AUTOSAR XML (schema 4-3-0)
package /ComponentTypes
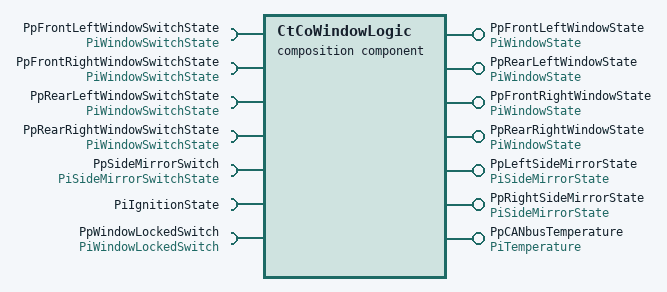
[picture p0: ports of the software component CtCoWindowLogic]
  composition sw component type CtCoWindowLogic
    5 x require port:
      PpFrontLeftWindowSwitchState: nonqueued-receiver-com-spec{data-element=DeWindowSwitchState, init-value=0}, required-interface=PiWindowSwitchState
      PpFrontRightWindowSwitchState: nonqueued-receiver-com-spec{data-element=DeWindowSwitchState, init-value=0}, required-interface=PiWindowSwitchState
      PpRearLeftWindowSwitchState: nonqueued-receiver-com-spec{data-element=DeWindowSwitchState, init-value=0}, required-interface=PiWindowSwitchState
      PpRearRightWindowSwitchState: nonqueued-receiver-com-spec{data-element=DeWindowSwitchState, init-value=0}, required-interface=PiWindowSwitchState
      PpSideMirrorSwitch: nonqueued-receiver-com-spec{data-element=DeSideMirrorSelectionState, filter=data-filter-type=ALWAYS, init-value=0}, required-interface=PiSideMirrorSwitchState
    6 x provide port:
      PpFrontLeftWindowState: nonqueued-sender-com-spec=DeWindowState, provided-interface=PiWindowState
      PpRearLeftWindowState: nonqueued-sender-com-spec=DeWindowState, provided-interface=PiWindowState
      PpFrontRightWindowState: nonqueued-sender-com-spec=DeWindowState, provided-interface=PiWindowState
      PpRearRightWindowState: nonqueued-sender-com-spec=DeWindowState, provided-interface=PiWindowState
      PpLeftSideMirrorState: provided-interface=PiSideMirrorState
      PpRightSideMirrorState: provided-interface=PiSideMirrorState
    require port PiIgnitionState: nonqueued-receiver-com-spec{data-element=DeIgnitionState, init-value=0}, required-interface=PiIgnitionState
    require port PpWindowLockedSwitch: nonqueued-receiver-com-spec{data-element=DeWindowLock, init-value=0}, required-interface=PiWindowLockedSwitch  # This Port will accept incoming boolean value from the connected actuator. If the value returns yes(trigger) the runnable will run.
    provide port PpCANbusTemperature: nonqueued-sender-com-spec=DeTemp, provided-interface=PiTemperature
    5 x component:
      CpAtWindowSwitchDecoder: type=CtAtWindowSwitchDecoder
      CtAtSideMirrorDecoder: type=CtAtSideMirrorDecoder
      CtAtWindowOpener: type=CtAtWindowOpener
      CtSaJoypadY: type=CtSaJoypadY
      CtSaJoypadX: type=CtSaJoypadX
    delegate CpAtWindowSwitchDecoder.PpFrontLeftWindowSwitchState <-> outer port PpFrontLeftWindowSwitchState
    delegate CpAtWindowSwitchDecoder.PpFrontRightWindowSwitchState <-> outer port PpFrontRightWindowSwitchState
    delegate CpAtWindowSwitchDecoder.PpRearLeftWindowSwitchState <-> outer port PpRearLeftWindowSwitchState
    delegate CpAtWindowSwitchDecoder.PpRearRightWindowSwitchState <-> outer port PpRearRightWindowSwitchState
    connect CpAtWindowSwitchDecoder.PpFrontLeftWindowState -> CtAtWindowOpener.PpInFrontLeftWindowState
    connect CpAtWindowSwitchDecoder.PpFrontRightWindowState -> CtAtWindowOpener.PpInFrontRightWindowState
    connect CpAtWindowSwitchDecoder.PpRearLeftWindowState -> CtAtWindowOpener.PpInRearLeftWindowState
    connect CpAtWindowSwitchDecoder.PpRearRightWindowState -> CtAtWindowOpener.PpInRearRightWindowState
    delegate CtAtSideMirrorDecoder.PpSideMirrorSwitchState <-> outer port PpSideMirrorSwitch
    delegate CtAtWindowOpener.PpOutLeftSideMirrorState <-> outer port PpLeftSideMirrorState
    delegate CtAtWindowOpener.PpOutRightSideMirrorState <-> outer port PpRightSideMirrorState
    delegate CtAtWindowOpener.PpOutFrontLeftWindowState <-> outer port PpFrontLeftWindowState
    delegate CtAtWindowOpener.PpOutFrontRightWindowState <-> outer port PpFrontRightWindowState
    delegate CtAtWindowOpener.PpOutRearLeftWindowState <-> outer port PpRearLeftWindowState
    delegate CtAtWindowOpener.PpOutRearRightWindowState <-> outer port PpRearRightWindowState
    connect CtSaJoypadX.PpJoypadX -> CtAtSideMirrorDecoder.PpJoypadX
    connect CtSaJoypadY.PpJoypadY -> CtAtSideMirrorDecoder.PpJoypadY
    delegate CpAtWindowSwitchDecoder.PpWindowLockedSwitch <-> outer port PpWindowLockedSwitch
    connect CtAtSideMirrorDecoder.PpLeftSideMirrorState -> CtAtWindowOpener.PpInLeftSideMirrorState
    connect CtAtSideMirrorDecoder.PpRightSideMirrorState -> CtAtWindowOpener.PpInRightSideMirrorState
    delegate CtAtWindowOpener.PpIgnitionState <-> outer port PiIgnitionState
    delegate CtAtWindowOpener.PpTemperature <-> outer port PpCANbusTemperature
